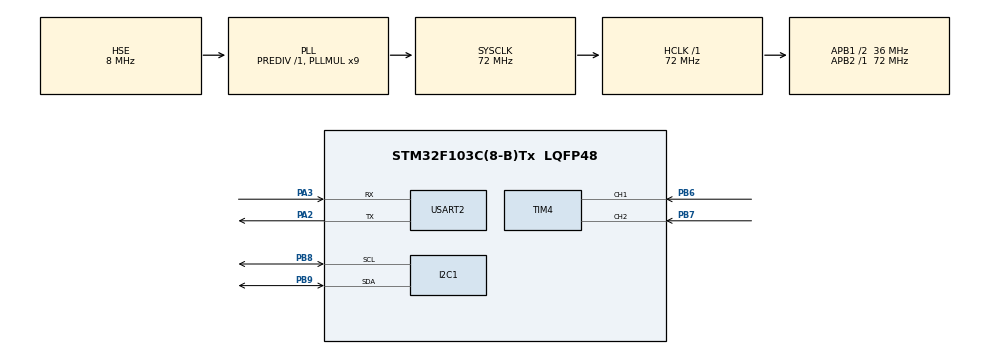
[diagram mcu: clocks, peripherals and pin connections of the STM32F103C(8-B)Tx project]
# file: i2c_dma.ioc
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Dma.I2C1_RX.0.Direction=DMA_PERIPH_TO_MEMORY
Dma.I2C1_RX.0.Instance=DMA1_Channel7
Dma.I2C1_RX.0.MemDataAlignment=DMA_MDATAALIGN_BYTE
Dma.I2C1_RX.0.MemInc=DMA_MINC_ENABLE
Dma.I2C1_RX.0.Mode=DMA_NORMAL
Dma.I2C1_RX.0.PeriphDataAlignment=DMA_PDATAALIGN_BYTE
Dma.I2C1_RX.0.PeriphInc=DMA_PINC_DISABLE
Dma.I2C1_RX.0.Priority=DMA_PRIORITY_LOW
Dma.I2C1_TX.1.Direction=DMA_MEMORY_TO_PERIPH
Dma.I2C1_TX.1.Instance=DMA1_Channel6
Dma.I2C1_TX.1.MemDataAlignment=DMA_MDATAALIGN_BYTE
Dma.I2C1_TX.1.MemInc=DMA_MINC_ENABLE
Dma.I2C1_TX.1.Mode=DMA_NORMAL
Dma.I2C1_TX.1.PeriphDataAlignment=DMA_PDATAALIGN_BYTE
Dma.I2C1_TX.1.PeriphInc=DMA_PINC_DISABLE
Dma.I2C1_TX.1.Priority=DMA_PRIORITY_LOW
Dma.Request0=I2C1_RX
Dma.Request1=I2C1_TX
Mcu.Family=STM32F1
Mcu.Name=STM32F103C(8-B)Tx
Mcu.Package=LQFP48
NVIC.DMA1_Channel6_IRQn=true\:0\:0\:false\:false\:true\:false\:true
NVIC.DMA1_Channel7_IRQn=true\:0\:0\:false\:false\:true\:false\:true
NVIC.PriorityGroup=NVIC_PRIORITYGROUP_4
PA13.Mode=Serial_Wire
PA13.Signal=SYS_JTMS-SWDIO
PA14.Mode=Serial_Wire
PA14.Signal=SYS_JTCK-SWCLK
PA2.Mode=Asynchronous
PA2.Signal=USART2_TX
PA3.Mode=Asynchronous
PA3.Signal=USART2_RX
PB6.Signal=S_TIM4_CH1
PB7.Signal=S_TIM4_CH2
PB8.Mode=I2C
PB8.Signal=I2C1_SCL
PB9.Mode=I2C
PB9.Signal=I2C1_SDA
PD0-OSC_IN.Mode=HSE-External-Oscillator
PD0-OSC_IN.Signal=RCC_OSC_IN
PD1-OSC_OUT.Mode=HSE-External-Oscillator
PD1-OSC_OUT.Signal=RCC_OSC_OUT
ProjectManager.HeapSize=0x200
ProjectManager.StackSize=0x400
ProjectManager.TargetToolchain=STM32CubeIDE
RCC.AHBFreq_Value=72000000
RCC.APB1CLKDivider=RCC_HCLK_DIV2
RCC.APB1Freq_Value=36000000
RCC.APB1TimFreq_Value=72000000
RCC.APB2Freq_Value=72000000
RCC.APB2TimFreq_Value=72000000
RCC.HCLKFreq_Value=72000000
RCC.PLLMUL=RCC_PLL_MUL9
RCC.PLLSourceVirtual=RCC_PLLSOURCE_HSE
RCC.SYSCLKFreq_VALUE=72000000
RCC.SYSCLKSource=RCC_SYSCLKSOURCE_PLLCLK
RCC.USBFreq_Value=48000000
RCC.USBPrescaler=RCC_USBCLKSOURCE_PLL_DIV1_5
SH.S_TIM4_CH1.0=TIM4_CH1,Encoder_Interface
SH.S_TIM4_CH2.0=TIM4_CH2,Encoder_Interface
USART2.VirtualMode=VM_ASYNC
board=custom

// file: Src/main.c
/* USER CODE BEGIN Header */
/**
  ******************************************************************************
  * @file           : main.c
  * @brief          : Main program body
  ******************************************************************************
  * @attention
  *
  * <h2><center>&copy; Copyright (c) 2019 STMicroelectronics.
  * All rights reserved.</center></h2>
  *
  * This software component is licensed by ST under BSD 3-Clause license,
  * the "License"; You may not use this file except in compliance with the
  * License. You may obtain a copy of the License at:
  *                        opensource.org/licenses/BSD-3-Clause
  *
  ******************************************************************************
  */
/* USER CODE END Header */

#include "main.h"

/* USER CODE BEGIN Includes */
#include "mpu6050.h"
/* USER CODE END Includes */

I2C_HandleTypeDef hi2c1;
DMA_HandleTypeDef hdma_i2c1_rx;
DMA_HandleTypeDef hdma_i2c1_tx;

TIM_HandleTypeDef htim4;

UART_HandleTypeDef huart2;

void SystemClock_Config(void);
static void MX_GPIO_Init(void);
static void MX_DMA_Init(void);
static void MX_I2C1_Init(void);
static void MX_TIM4_Init(void);
static void MX_USART2_UART_Init(void);

int main(void)
{

  /* MCU Configuration--------------------------------------------------------*/

  /* Reset of all peripherals, Initializes the Flash interface and the Systick. */
  HAL_Init();

  /* Configure the system clock */
  SystemClock_Config();

  /* Initialize all configured peripherals */
  MX_GPIO_Init();
  MX_DMA_Init();
  MX_I2C1_Init();
  MX_TIM4_Init();
  MX_USART2_UART_Init();
  /* USER CODE BEGIN 2 */
  init_MPU();
  /* USER CODE END 2 */

  /* Infinite loop */
  while (1)
  {

    /* USER CODE BEGIN 3 */
	  process_MPU();
	  //HAL_Delay(100);
  }
  /* USER CODE END 3 */
}

void SystemClock_Config(void)
{
  RCC_OscInitTypeDef RCC_OscInitStruct = {0};
  RCC_ClkInitTypeDef RCC_ClkInitStruct = {0};

  /** Initializes the CPU, AHB and APB busses clocks
  */
  RCC_OscInitStruct.OscillatorType = RCC_OSCILLATORTYPE_HSE;
  RCC_OscInitStruct.HSEState = RCC_HSE_ON;
  RCC_OscInitStruct.HSEPredivValue = RCC_HSE_PREDIV_DIV1;
  RCC_OscInitStruct.HSIState = RCC_HSI_ON;
  RCC_OscInitStruct.PLL.PLLState = RCC_PLL_ON;
  RCC_OscInitStruct.PLL.PLLSource = RCC_PLLSOURCE_HSE;
  RCC_OscInitStruct.PLL.PLLMUL = RCC_PLL_MUL9;
  if (HAL_RCC_OscConfig(&RCC_OscInitStruct) != HAL_OK)
  {
    Error_Handler();
  }
  /** Initializes the CPU, AHB and APB busses clocks
  */
  RCC_ClkInitStruct.ClockType = RCC_CLOCKTYPE_HCLK|RCC_CLOCKTYPE_SYSCLK
                              |RCC_CLOCKTYPE_PCLK1|RCC_CLOCKTYPE_PCLK2;
  RCC_ClkInitStruct.SYSCLKSource = RCC_SYSCLKSOURCE_PLLCLK;
  RCC_ClkInitStruct.AHBCLKDivider = RCC_SYSCLK_DIV1;
  RCC_ClkInitStruct.APB1CLKDivider = RCC_HCLK_DIV2;
  RCC_ClkInitStruct.APB2CLKDivider = RCC_HCLK_DIV1;

  if (HAL_RCC_ClockConfig(&RCC_ClkInitStruct, FLASH_LATENCY_2) != HAL_OK)
  {
    Error_Handler();
  }
}

static void MX_I2C1_Init(void)
{

  hi2c1.Instance = I2C1;
  hi2c1.Init.ClockSpeed = 100000;
  hi2c1.Init.DutyCycle = I2C_DUTYCYCLE_2;
  hi2c1.Init.OwnAddress1 = 0;
  hi2c1.Init.AddressingMode = I2C_ADDRESSINGMODE_7BIT;
  hi2c1.Init.DualAddressMode = I2C_DUALADDRESS_DISABLE;
  hi2c1.Init.OwnAddress2 = 0;
  hi2c1.Init.GeneralCallMode = I2C_GENERALCALL_DISABLE;
  hi2c1.Init.NoStretchMode = I2C_NOSTRETCH_DISABLE;
  if (HAL_I2C_Init(&hi2c1) != HAL_OK)
  {
    Error_Handler();
  }

}

static void MX_TIM4_Init(void)
{

  TIM_Encoder_InitTypeDef sConfig = {0};
  TIM_MasterConfigTypeDef sMasterConfig = {0};

  htim4.Instance = TIM4;
  htim4.Init.Prescaler = 0;
  htim4.Init.CounterMode = TIM_COUNTERMODE_UP;
  htim4.Init.Period = 0;
  htim4.Init.ClockDivision = TIM_CLOCKDIVISION_DIV1;
  htim4.Init.AutoReloadPreload = TIM_AUTORELOAD_PRELOAD_DISABLE;
  sConfig.EncoderMode = TIM_ENCODERMODE_TI1;
  sConfig.IC1Polarity = TIM_ICPOLARITY_RISING;
  sConfig.IC1Selection = TIM_ICSELECTION_DIRECTTI;
  sConfig.IC1Prescaler = TIM_ICPSC_DIV1;
  sConfig.IC1Filter = 0;
  sConfig.IC2Polarity = TIM_ICPOLARITY_RISING;
  sConfig.IC2Selection = TIM_ICSELECTION_DIRECTTI;
  sConfig.IC2Prescaler = TIM_ICPSC_DIV1;
  sConfig.IC2Filter = 0;
  if (HAL_TIM_Encoder_Init(&htim4, &sConfig) != HAL_OK)
  {
    Error_Handler();
  }
  sMasterConfig.MasterOutputTrigger = TIM_TRGO_RESET;
  sMasterConfig.MasterSlaveMode = TIM_MASTERSLAVEMODE_DISABLE;
  if (HAL_TIMEx_MasterConfigSynchronization(&htim4, &sMasterConfig) != HAL_OK)
  {
    Error_Handler();
  }

}

static void MX_USART2_UART_Init(void)
{

  huart2.Instance = USART2;
  huart2.Init.BaudRate = 115200;
  huart2.Init.WordLength = UART_WORDLENGTH_8B;
  huart2.Init.StopBits = UART_STOPBITS_1;
  huart2.Init.Parity = UART_PARITY_NONE;
  huart2.Init.Mode = UART_MODE_TX_RX;
  huart2.Init.HwFlowCtl = UART_HWCONTROL_NONE;
  huart2.Init.OverSampling = UART_OVERSAMPLING_16;
  if (HAL_UART_Init(&huart2) != HAL_OK)
  {
    Error_Handler();
  }

}

static void MX_DMA_Init(void)
{

  /* DMA controller clock enable */
  __HAL_RCC_DMA1_CLK_ENABLE();

  /* DMA interrupt init */
  /* DMA1_Channel6_IRQn interrupt configuration */
  HAL_NVIC_SetPriority(DMA1_Channel6_IRQn, 0, 0);
  HAL_NVIC_EnableIRQ(DMA1_Channel6_IRQn);
  /* DMA1_Channel7_IRQn interrupt configuration */
  HAL_NVIC_SetPriority(DMA1_Channel7_IRQn, 0, 0);
  HAL_NVIC_EnableIRQ(DMA1_Channel7_IRQn);

}

static void MX_GPIO_Init(void)
{

  /* GPIO Ports Clock Enable */
  __HAL_RCC_GPIOD_CLK_ENABLE();
  __HAL_RCC_GPIOA_CLK_ENABLE();
  __HAL_RCC_GPIOB_CLK_ENABLE();

}

/* USER CODE BEGIN 4 */
void HAL_I2C_MasterRxCpltCallback(I2C_HandleTypeDef *hi2c)
{
  /* Prevent unused argument(s) compilation warning */
  __NOP();
  /* NOTE : This function should not be modified, when the callback is needed,
            the HAL_I2C_MasterRxCpltCallback could be implemented in the user file
   */
}

void HAL_I2C_MasterTxCpltCallback(I2C_HandleTypeDef *hi2c)
{
  /* Prevent unused argument(s) compilation warning */
  __NOP();
  /* NOTE : This function should not be modified, when the callback is needed,
            the HAL_I2C_MasterRxCpltCallback could be implemented in the user file
   */
}
/* USER CODE END 4 */

void Error_Handler(void)
{
}

/************************ (C) COPYRIGHT STMicroelectronics *****END OF FILE****/
